# STM32U3C5 register map
File version: 1.0
CPU: CM33 r0p1, little endian, MPU, FPU, 4 interrupt priority bits
Registers are 32-bit, read-write, reset 0x0 unless marked. A register's access mark holds for its fields unless they carry their own. Offsets are from the block's base; [hi:lo] are bit positions; lines under a group give offsets from that group; {n}, {i} and the like mark numbered series; 'fields as' and 'values as' point back to an identical list.

## TSC — TSC address block description
Base 0x40024000
Same registers: SEC_TSC 0x50024000
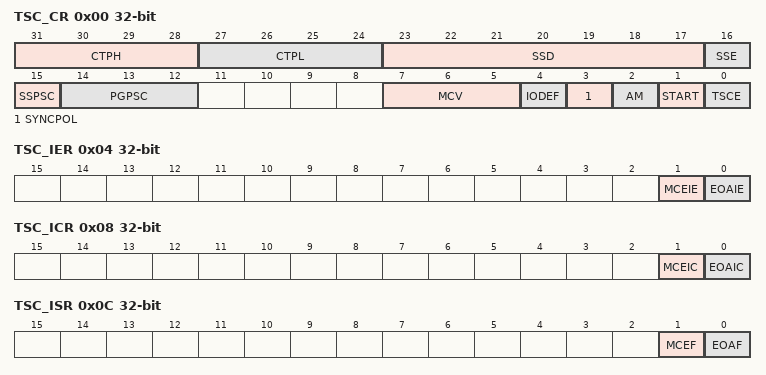
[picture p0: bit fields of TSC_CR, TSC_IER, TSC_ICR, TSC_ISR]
0x00 TSC_CR — TSC control register
  [31:28] CTPH — Charge transfer pulse high
    0=1x tless thansub>PGCLKless than/sub>; 1=2x tless thansub>PGCLKless than/sub>; 15=16x tless thansub>PGCLKless than/sub>
  [27:24] CTPL — Charge transfer pulse low
    values as CTPH
  [23:17] SSD — Spread spectrum deviation
    0=1x tless thansub>SSCLKless than/sub>; 1=2x tless thansub>SSCLKless than/sub>; 127=128x tless thansub>SSCLKless than/sub>
  [16] SSE — Spread spectrum enable
    0=Spread spectrum disabled; 1=Spread spectrum enabled
  [15] SSPSC — Spread spectrum prescaler
    0=fless thansub>HCLKless than/sub>; 1=fless thansub>HCLKless than/sub> /2
  [14:12] PGPSC — Pulse generator prescaler
    0=fless thansub>HCLKless than/sub>; 1=fless thansub>HCLKless than/sub> /2; 2=fless thansub>HCLKless than/sub> /4; 3=fless thansub>HCLKless than/sub> /8; 4=fless thansub>HCLKless than/sub> /16; 5=fless thansub>HCLKless than/sub> /32; 6=fless thansub>HCLKless than/sub> /64; 7=fless thansub>HCLKless than/sub> /128
  [7:5] MCV — Max count value
    0=255; 1=511; 2=1023; 3=2047; 4=4095; 5=8191; 6=16383
  [4] IODEF — I/O Default mode
    0=I/Os are forced to output push-pull low; 1=I/Os are in input floating
  [3] SYNCPOL — Synchronization pin polarity
    0=Falling edge only; 1=Rising edge and high level
  [2] AM — Acquisition mode
    0=Normal acquisition mode (acquisition starts as soon as START bit is set); 1=Synchronized acquisition mode (acquisition starts if START bit is set and when the selected signal is detected on the SYNC input pin)
  [1] START — Start a new acquisition
    0=Acquisition not started; 1=Start a new acquisition
  [0] TSCE — Touch sensing controller enable
    0=Touch sensing controller disabled; 1=Touch sensing controller enabled
0x04 TSC_IER — TSC interrupt enable register
  [1] MCEIE — Max count error interrupt enable
    0=Max count error interrupt disabled; 1=Max count error interrupt enabled
  [0] EOAIE — End of acquisition interrupt enable
    0=End of acquisition interrupt disabled; 1=End of acquisition interrupt enabled
0x08 TSC_ICR — TSC interrupt clear register
  [1] MCEIC — Max count error interrupt clear
    0=No effect; 1=Clears the corresponding MCEF of the TSC_ISR register
  [0] EOAIC — End of acquisition interrupt clear
    0=No effect; 1=Clears the corresponding EOAF of the TSC_ISR register
0x0C TSC_ISR ro — TSC interrupt status register
  [1] MCEF — Max count error flag
    0=No max count error (MCE) detected; 1=Max count error (MCE) detected
  [0] EOAF — End of acquisition flag
    0=Acquisition is ongoing or not started; 1=Acquisition is complete
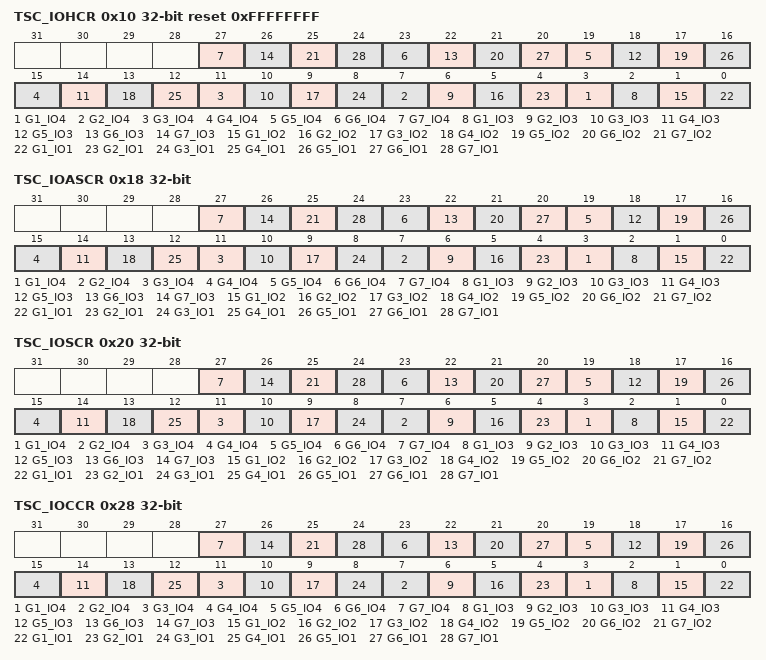
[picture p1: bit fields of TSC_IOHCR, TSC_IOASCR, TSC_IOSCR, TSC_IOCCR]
0x10 TSC_IOHCR reset 0xFFFFFFFF — TSC I/O hysteresis control register
  [all] fields
    0=Gx_IOy Schmitt trigger hysteresis disabled; 1=Gx_IOy Schmitt trigger hysteresis enabled
  [4n-1] G{n}_IO4 (n=1..7) — Gx_IOy Schmitt trigger hysteresis mode
  [4n-2] G{n}_IO3 (n=1..7) — Gx_IOy Schmitt trigger hysteresis mode
  [4n-3] G{n}_IO2 (n=1..7) — Gx_IOy Schmitt trigger hysteresis mode
  [4n-4] G{n}_IO1 (n=1..7) — Gx_IOy Schmitt trigger hysteresis mode
0x18 TSC_IOASCR — TSC I/O analog switch control register
  [all] fields
    0=Gx_IOy analog switch disabled (opened); 1=Gx_IOy analog switch enabled (closed)
  [4n-1] G{n}_IO4 (n=1..7) — Gx_IOy analog switch enable
  [4n-2] G{n}_IO3 (n=1..7) — Gx_IOy analog switch enable
  [4n-3] G{n}_IO2 (n=1..7) — Gx_IOy analog switch enable
  [4n-4] G{n}_IO1 (n=1..7) — Gx_IOy analog switch enable
0x20 TSC_IOSCR — TSC I/O sampling control register
  [all] fields
    0=Gx_IOy unused; 1=Gx_IOy used as sampling capacitor
  [4n-1] G{n}_IO4 (n=1..7) — Gx_IOy sampling mode
  [4n-2] G{n}_IO3 (n=1..7) — Gx_IOy sampling mode
  [4n-3] G{n}_IO2 (n=1..7) — Gx_IOy sampling mode
  [4n-4] G{n}_IO1 (n=1..7) — Gx_IOy sampling mode
0x28 TSC_IOCCR — TSC I/O channel control register
  [all] fields
    0=Gx_IOy unused; 1=Gx_IOy used as channel
  [4n-1] G{n}_IO4 (n=1..7) — Gx_IOy channel mode
  [4n-2] G{n}_IO3 (n=1..7) — Gx_IOy channel mode
  [4n-3] G{n}_IO2 (n=1..7) — Gx_IOy channel mode
  [4n-4] G{n}_IO1 (n=1..7) — Gx_IOy channel mode
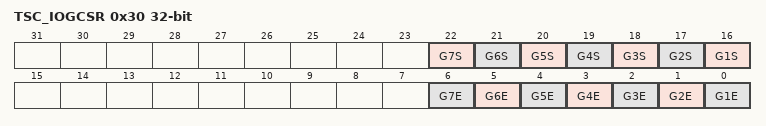
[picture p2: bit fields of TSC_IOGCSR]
0x30 TSC_IOGCSR — TSC I/O group control status register
  [n+15] G{n}S ro (n=1..7) — Analog I/O group x status
    0=Acquisition on analog I/O group x is ongoing or not started; 1=Acquisition on analog I/O group x is complete
  [n-1] G{n}E (n=1..7) — Analog I/O group x enable
    0=Acquisition on analog I/O group x disabled; 1=Acquisition on analog I/O group x enabled
{0x30+4i} TSC_IOG{i}CR ro (i=1..7) — TSC I/O group {i} counter register
  [13:0] CNT — Counter value
